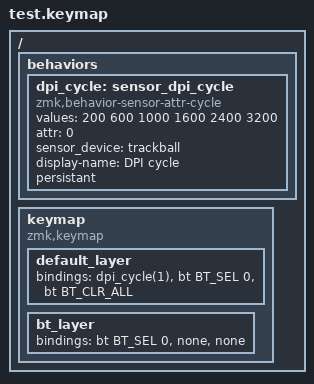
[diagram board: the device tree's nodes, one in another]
#include <behaviors.dtsi>
#include <dt-bindings/zmk/keys.h>
#include <dt-bindings/zmk/bt.h>

/ {
    behaviors {
        // Behaviour to cycle through DPI values on a keypress
        dpi_cycle: sensor_dpi_cycle {
            compatible = "zmk,behavior-sensor-attr-cycle";
            #binding-cells = <1>;
            values = < 200 600 1000 1600 2400 3200 >;
            attr = <0>;
            sensor_device = <&trackball>;
            display-name = "DPI cycle";
            persistant;
        };
    };

    keymap {
        compatible = "zmk,keymap";

        default_layer { // Layer 0
            // -------------
            // |     Z     |
            // |     A     |
            // |     D     |
            bindings = <
                &dpi_cycle(1)
                &bt BT_SEL 0
                &bt BT_CLR_ALL
            >;
        };

        bt_layer { // bluetooth layer
            bindings = <
                &bt BT_SEL 0
                &none
                &none
            >;
        };
    };
 };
